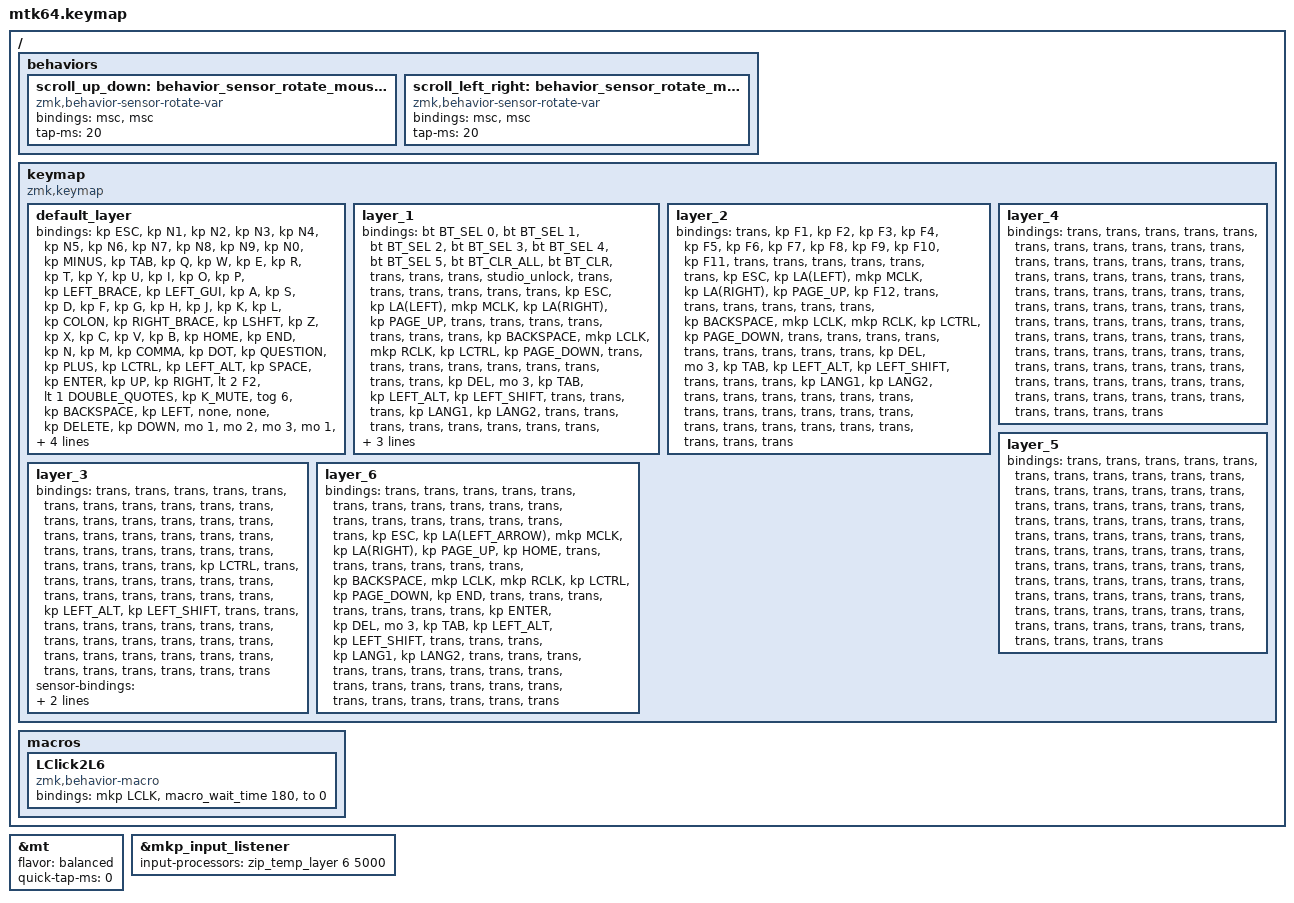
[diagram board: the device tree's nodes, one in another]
#include <input/processors.dtsi>
#include <behaviors.dtsi>
#include <dt-bindings/zmk/bt.h>
#include <dt-bindings/zmk/keys.h>
#include <dt-bindings/zmk/pointing.h>
#include "keycode_japanese.h"

// スクロール量の設定

#define ZMK_POINTING_DEFAULT_SCRL_VAL 100

&mt {
    flavor = "balanced";
    quick-tap-ms = <0>;
};

&mkp_input_listener { input-processors = <&zip_temp_layer 6 5000>; };

/ {
    behaviors {
        // 垂直スクロール用のbehaviorの設定

        scroll_up_down: behavior_sensor_rotate_mouse_wheel_up_down {
            compatible = "zmk,behavior-sensor-rotate-var";
            #sensor-binding-cells = <2>;
            bindings = <&msc>, <&msc>;

            tap-ms = <20>; // スクロールのタップ時間
        };

        // 水平スクロール用のbehaviorの設定

        scroll_left_right: behavior_sensor_rotate_mouse_wheel_left_right {
            compatible = "zmk,behavior-sensor-rotate-var";
            #sensor-binding-cells = <2>;
            bindings = <&msc>, <&msc>;

            tap-ms = <20>; // スクロールのタップ時間
        };
    };
};

/ {
    keymap {
        compatible = "zmk,keymap";

        default_layer {
            bindings = <
&kp ESC  &kp N1  &kp N2  &kp N3  &kp N4  &kp N5  &kp N6  &kp N7  &kp N8  &kp N9  &kp N0  &kp MINUS  &kp TAB  &kp Q  &kp W  &kp E  &kp R  &kp T  &kp Y  &kp U  &kp I  &kp O  &kp P  &kp LEFT_BRACE  &kp LEFT_GUI  &kp A  &kp S  &kp D  &kp F  &kp G  &kp H  &kp J  &kp K  &kp L  &kp COLON  &kp RIGHT_BRACE  &kp LSHFT  &kp Z  &kp X  &kp C  &kp V  &kp B  &kp HOME  &kp END  &kp N  &kp M  &kp COMMA  &kp DOT  &kp QUESTION  &kp PLUS  &kp LCTRL  &kp LEFT_ALT  &kp SPACE  &kp ENTER  &kp UP  &kp RIGHT  &lt 2 F2  &lt 1 DOUBLE_QUOTES  &kp K_MUTE  &tog 6  &kp BACKSPACE  &kp LEFT  &none  &none  &kp DELETE  &kp DOWN  &mo 1  &mo 2  &mo 3  &mo 1  &mo 2  &mo 3  &mo 1  &mo 2  &mo 3
            >;

            sensor-bindings =
                <&inc_dec_kp C_VOLUME_DOWN C_VOLUME_UP>,
                <&scroll_up_down SCRL_UP SCRL_DOWN>;
        };

        layer_1 {
            bindings = <
&bt BT_SEL 0  &bt BT_SEL 1  &bt BT_SEL 2  &bt BT_SEL 3  &bt BT_SEL 4  &bt BT_SEL 5  &bt BT_CLR_ALL  &bt BT_CLR  &trans  &trans  &trans  &studio_unlock  &trans  &trans  &trans  &trans  &trans  &trans  &kp ESC  &kp LA(LEFT)  &mkp MCLK  &kp LA(RIGHT)  &kp PAGE_UP  &trans  &trans  &trans  &trans  &trans  &trans  &trans  &kp BACKSPACE  &mkp LCLK  &mkp RCLK  &kp LCTRL  &kp PAGE_DOWN  &trans  &trans  &trans  &trans  &trans  &trans  &trans  &trans  &trans  &kp DEL  &mo 3  &kp TAB  &kp LEFT_ALT  &kp LEFT_SHIFT  &trans  &trans  &trans  &kp LANG1  &kp LANG2  &trans  &trans  &trans  &trans  &trans  &trans  &trans  &trans  &trans  &trans  &trans  &trans  &trans  &trans  &trans  &trans  &trans  &trans  &trans  &trans  &trans
            >;
        };

        layer_2 {
            bindings = <
&trans  &kp F1  &kp F2  &kp F3  &kp F4  &kp F5  &kp F6  &kp F7  &kp F8  &kp F9  &kp F10  &kp F11  &trans  &trans  &trans  &trans  &trans  &trans  &kp ESC  &kp LA(LEFT)  &mkp MCLK  &kp LA(RIGHT)  &kp PAGE_UP  &kp F12  &trans  &trans  &trans  &trans  &trans  &trans  &kp BACKSPACE  &mkp LCLK  &mkp RCLK  &kp LCTRL  &kp PAGE_DOWN  &trans  &trans  &trans  &trans  &trans  &trans  &trans  &trans  &trans  &kp DEL  &mo 3  &kp TAB  &kp LEFT_ALT  &kp LEFT_SHIFT  &trans  &trans  &trans  &kp LANG1  &kp LANG2  &trans  &trans  &trans  &trans  &trans  &trans  &trans  &trans  &trans  &trans  &trans  &trans  &trans  &trans  &trans  &trans  &trans  &trans  &trans  &trans  &trans
            >;
        };

        layer_3 {
            bindings = <
&trans  &trans  &trans  &trans  &trans  &trans  &trans  &trans  &trans  &trans  &trans  &trans  &trans  &trans  &trans  &trans  &trans  &trans  &trans  &trans  &trans  &trans  &trans  &trans  &trans  &trans  &trans  &trans  &trans  &trans  &trans  &trans  &trans  &kp LCTRL  &trans  &trans  &trans  &trans  &trans  &trans  &trans  &trans  &trans  &trans  &trans  &trans  &trans  &kp LEFT_ALT  &kp LEFT_SHIFT  &trans  &trans  &trans  &trans  &trans  &trans  &trans  &trans  &trans  &trans  &trans  &trans  &trans  &trans  &trans  &trans  &trans  &trans  &trans  &trans  &trans  &trans  &trans  &trans  &trans  &trans
            >;

            sensor-bindings = <
                &scroll_left_right SCRL_LEFT SCRL_RIGHT
                &scroll_up_down SCRL_UP SCRL_DOWN
            >;
        };

        layer_4 {
            bindings = <
&trans  &trans  &trans  &trans  &trans  &trans  &trans  &trans  &trans  &trans  &trans  &trans  &trans  &trans  &trans  &trans  &trans  &trans  &trans  &trans  &trans  &trans  &trans  &trans  &trans  &trans  &trans  &trans  &trans  &trans  &trans  &trans  &trans  &trans  &trans  &trans  &trans  &trans  &trans  &trans  &trans  &trans  &trans  &trans  &trans  &trans  &trans  &trans  &trans  &trans  &trans  &trans  &trans  &trans  &trans  &trans  &trans  &trans  &trans  &trans  &trans  &trans  &trans  &trans  &trans  &trans  &trans  &trans  &trans  &trans  &trans  &trans  &trans  &trans  &trans
            >;
        };

        layer_5 {
            bindings = <
&trans  &trans  &trans  &trans  &trans  &trans  &trans  &trans  &trans  &trans  &trans  &trans  &trans  &trans  &trans  &trans  &trans  &trans  &trans  &trans  &trans  &trans  &trans  &trans  &trans  &trans  &trans  &trans  &trans  &trans  &trans  &trans  &trans  &trans  &trans  &trans  &trans  &trans  &trans  &trans  &trans  &trans  &trans  &trans  &trans  &trans  &trans  &trans  &trans  &trans  &trans  &trans  &trans  &trans  &trans  &trans  &trans  &trans  &trans  &trans  &trans  &trans  &trans  &trans  &trans  &trans  &trans  &trans  &trans  &trans  &trans  &trans  &trans  &trans  &trans
            >;
        };

        layer_6 {
            bindings = <
&trans  &trans  &trans  &trans  &trans  &trans  &trans  &trans  &trans  &trans  &trans  &trans  &trans  &trans  &trans  &trans  &trans  &trans  &kp ESC  &kp LA(LEFT_ARROW)  &mkp MCLK  &kp LA(RIGHT)  &kp PAGE_UP  &kp HOME  &trans  &trans  &trans  &trans  &trans  &trans  &kp BACKSPACE  &mkp LCLK  &mkp RCLK  &kp LCTRL  &kp PAGE_DOWN  &kp END  &trans  &trans  &trans  &trans  &trans  &trans  &trans  &kp ENTER  &kp DEL  &mo 3  &kp TAB  &kp LEFT_ALT  &kp LEFT_SHIFT  &trans  &trans  &trans  &kp LANG1  &kp LANG2  &trans  &trans  &trans  &trans  &trans  &trans  &trans  &trans  &trans  &trans  &trans  &trans  &trans  &trans  &trans  &trans  &trans  &trans  &trans  &trans  &trans
            >;
        };
    };
};

/ {
    macros {
        LClick2L6: LClick2L6 {
            compatible = "zmk,behavior-macro";
            #binding-cells = <0>;
            bindings = <&mkp LCLK>, <&macro_wait_time 180>, <&to 0>;
        };
    };
};
